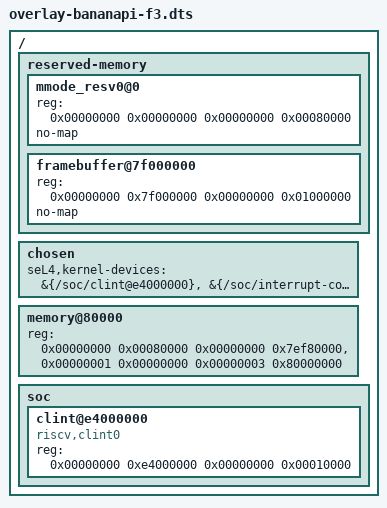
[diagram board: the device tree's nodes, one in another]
/*
 * Copyright 2025, 10xEngineers
 *
 * SPDX-License-Identifier: GPL-2.0-only
 */

/ {
    reserved-memory {
        /delete-node/ linux,cma;
    };

    chosen {
        seL4,kernel-devices =
            &{/soc/clint@e4000000},
            &{/soc/interrupt-controller@e0000000};
    };

    /*
    * Main memory layout
    *
    *   - Bank 0: usable DRAM from 0x00080000 (skipping first 512 KiB)
    *             up to 0x7f000000 (reserving final 16 MiB of the low 2 GiB).
    *   - Bank 1: usable DRAM from 0x100000000 (4 GiB) for ~14 GiB above.
    *
    *   Note: the 2–4 GiB physical window is omitted from use here.
    */
    memory@80000 {
        device_type = "memory";
        reg = <0x00000000 0x00080000 0x00000000 0x7ef80000>,
              <0x00000001 0x00000000 0x00000003 0x80000000>;
    };

    /*
     * According to the Spacemit K1 memory map the CLINT is mapped from
     * 0xe4000000 to 0xe4010000 (64 KiB region used for timer and IPIs).
     */
    soc {
        clint@e4000000 {
            compatible = "riscv,clint0";
            reg = <0x00000000 0xe4000000 0x00000000 0x00010000>;
        };
    };

    /*
     * Reserve memory regions that must not be used by seL4:
     * - (512 KiB): M-mode / OpenSBI
     * - (16 MiB): framebuffer / S-mode runtime
     */
    reserved-memory {
        #address-cells = <0x02>;
        #size-cells = <0x02>;
        ranges;

        mmode_resv0@0 {
            reg = <0x00000000 0x00000000 0x00000000 0x00080000>;
            no-map;
        };

        framebuffer@7f000000 {
            reg = <0x00000000 0x7f000000 0x00000000 0x01000000>;
            no-map;
        };
    };
};
